# EFR32FG23B010F512IM48 register map
Vendor: Silicon Labs; Series: EFR32; File version: C
CPU: CM33 r0p4, little endian, MPU, FPU, DSP, VTOR, 4 interrupt priority bits, 8 SAU regions
Registers are 32-bit, read-write, reset 0x0 unless marked. A register's access mark holds for its fields unless they carry their own. Offsets are from the block's base; [hi:lo] are bit positions.

## MSC_NS — MSC_NS Registers
Base 0x50030000
Same registers: MSC_S 0x40030000
0x00 IPVERSION ro reset 0x2
  [31:0] IPVERSION — IP Version ID
0x04 READCTRL reset 0x200000
  [21:20] MODE — Read Mode
    0=WS0 (Zero wait-states inserted in fetch or read transfers); 1=WS1 (One wait-state inserted for each fetch or read transfer. See Flash Wait-States table for details); 2=WS2 (Two wait-states inserted for eatch fetch or read transfer. See Flash Wait-States table for details); 3=WS3 (Three wait-states inserted for eatch fetch or read transfer. See Flash Wait-States table for details)
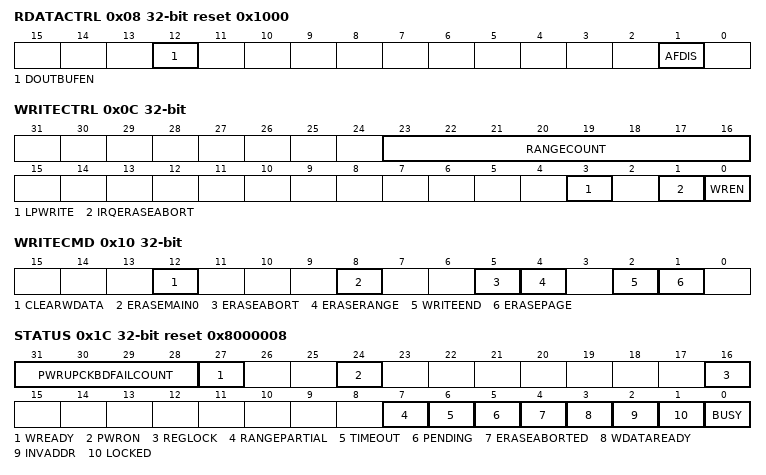
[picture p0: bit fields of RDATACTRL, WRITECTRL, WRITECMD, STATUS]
0x08 RDATACTRL reset 0x1000
  [12] DOUTBUFEN — Flash dout pipeline buffer enable
  [1] AFDIS — Automatic Invalidate Disable
0x0C WRITECTRL
  [23:16] RANGECOUNT — EraseRange Count
  [3] LPWRITE — Low-Power Write
  [1] IRQERASEABORT — Abort Page Erase on Interrupt
  [0] WREN — Enable Write/Erase Controller
0x10 WRITECMD wo
  [12] CLEARWDATA — Clear WDATA state
  [8] ERASEMAIN0 — Mass erase region 0
  [5] ERASEABORT — Abort erase sequence
  [4] ERASERANGE — Erase range of pages
  [2] WRITEEND — End Write Mode
  [1] ERASEPAGE
0x14 ADDRB
  [31:0] ADDRB — Page Erase or Write Address Buffer
0x18 WDATA
  [31:0] DATAW — Write Data
0x1C STATUS ro reset 0x8000008
  [31:28] PWRUPCKBDFAILCOUNT — Flash power up checkerboard pattern chec
  [27] WREADY — Flash Write Ready
  [24] PWRON — Flash power on status
  [16] REGLOCK — Register Lock Status
    0=UNLOCKED; 1=LOCKED
  [7] RANGEPARTIAL — EraseRange with skipped locked pages
  [6] TIMEOUT — Write Command Timeout
  [5] PENDING — Write Command In Queue
  [4] ERASEABORTED — Erase Operation Aborted
  [3] WDATAREADY — WDATA Write Ready
  [2] INVADDR — Invalid Write Address or Erase Page
  [1] LOCKED — Access Locked
  [0] BUSY — Erase/Write Busy
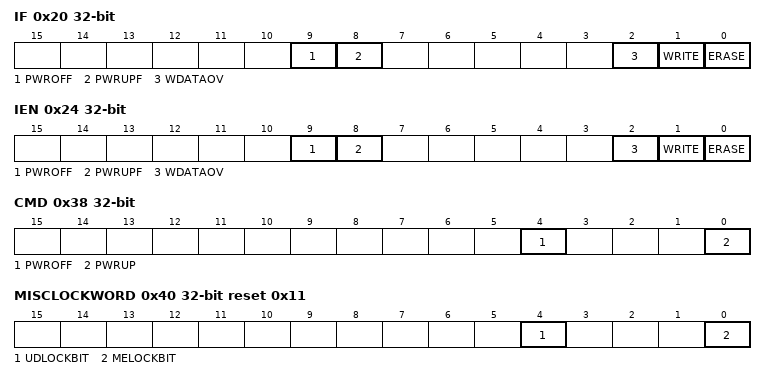
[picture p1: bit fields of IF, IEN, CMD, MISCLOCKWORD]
0x20 IF
  [9] PWROFF — Flash Power Off Sequence Complete Flag
  [8] PWRUPF — Flash Power Up Sequence Complete Flag
  [2] WDATAOV — Host write buffer overflow
  [1] WRITE — Host Write Done Interrupt Read Flag
  [0] ERASE — Host Erase Done Interrupt Read Flag
0x24 IEN
  [9] PWROFF — Flash Power Off Seq done irq enable
  [8] PWRUPF — Flash Power Up Seq done irq enable
  [2] WDATAOV — write data buffer overflow irq enable
  [1] WRITE — Write Done Interrupt enable
  [0] ERASE — Erase Done Interrupt enable
0x34 USERDATASIZE ro reset 0x4
  [5:0] USERDATASIZE
0x38 CMD wo
  [4] PWROFF — Flash power off/sleep command
  [0] PWRUP — Flash Power Up Command
0x3C LOCK wo
  [15:0] LOCKKEY — Configuration Lock
    0=LOCK; 0x1B71=UNLOCK
0x40 MISCLOCKWORD reset 0x11
  [4] UDLOCKBIT — User Data Lock
  [0] MELOCKBIT — Mass Erase Lock
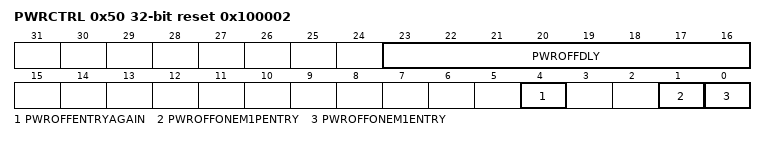
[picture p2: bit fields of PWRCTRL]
0x50 PWRCTRL reset 0x100002
  [23:16] PWROFFDLY — Power down delay
  [4] PWROFFENTRYAGAIN — POWER down flash again in EM1/EM1p
  [1] PWROFFONEM1PENTRY — Power down Flash macro when enter EM1P
  [0] PWROFFONEM1ENTRY — Power down Flash macro when enter EM1
0x120 PAGELOCK0
  [31:0] LOCKBIT — page lock bit
0x124 PAGELOCK1
  [31:0] LOCKBIT — page lock bit

## PFMXPPRF_NS — PFMXPPRF_NS Registers
Base 0x500C4000
Same registers: PFMXPPRF_S 0x400C4000
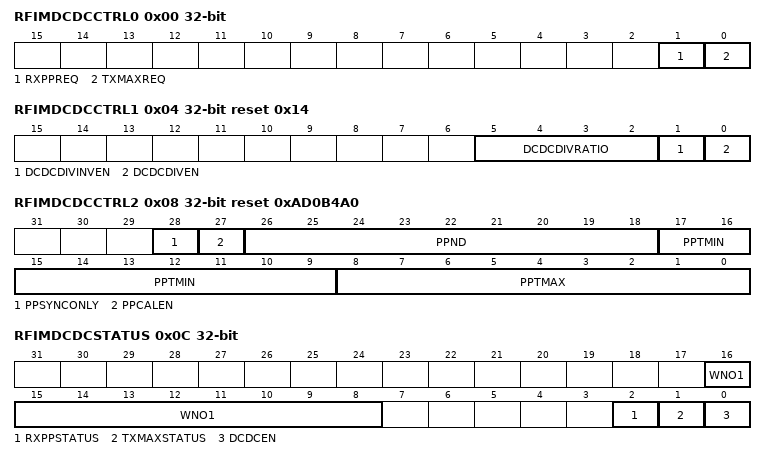
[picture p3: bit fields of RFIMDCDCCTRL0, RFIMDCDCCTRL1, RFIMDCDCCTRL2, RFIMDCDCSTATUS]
0x00 RFIMDCDCCTRL0
  [1] RXPPREQ, [0] TXMAXREQ
0x04 RFIMDCDCCTRL1 reset 0x14
  [5:2] DCDCDIVRATIO
    0=DIVRATIO8 (Dividing master_rf clk by 8, D=50%); 1=DIVRATIO9 (Dividing master_rf clk by 9, D=44.4%); 2=DIVRATIO10 (Dividing master_rf clk by 10, D=40%); 3=DIVRATIO11 (Dividing master_rf clk by 11, D=36.4%); 4=DIVRATIO12 (Dividing master_rf clk by 12, D=50%); 5=DIVRATIO13 (Dividing master_rf clk by 13, D=46.2%); 6=DIVRATIO14 (Dividing master_rf clk by 14, D=42.9%); 7=DIVRATIO15 (Dividing master_rf clk by 15, D=40%); 8=DIVRATIO16 (Dividing master_rf clk by 16, D=50%); 9=DIVRATIO17 (Dividing master_rf clk by 17, D=47.1%); 10=DIVRATIO18 (Dividing master_rf clk by 18, D=44.4%); 11=DIVRATIO19 (Dividing master_rf clk by 19, D=42.1%); 12=DIVRATIO20 (Dividing master_rf clk by 20, D=60%); 13=DIVRATIO21 (Dividing master_rf clk by 21, D=57.1%); 14=DIVRATIO22 (Dividing master_rf clk by 22, D=54.5%); 15=DIVRATIO23 (Dividing master_rf clk by 23, D=52.2%)
  [1] DCDCDIVINVEN — DCDC DIV Inverter Enable
  [0] DCDCDIVEN — DCDC DIV Enable
0x08 RFIMDCDCCTRL2 reset 0xAD0B4A0
  [28] PPSYNCONLY — Pulse Pairing Sync Only
  [27] PPCALEN — Pulse Pairing Calibration Loop Enable
  [26:18] PPND — Pulse Pairing Period
  [17:9] PPTMIN — Pulse Pairing Time Min
  [8:0] PPTMAX — Pulse Pairing Time Max
0x0C RFIMDCDCSTATUS ro
  [16:8] WNO1 — Cal Loop WNO1 value
  [2] RXPPSTATUS
  [1] TXMAXSTATUS
  [0] DCDCEN — DCDC Enable Status
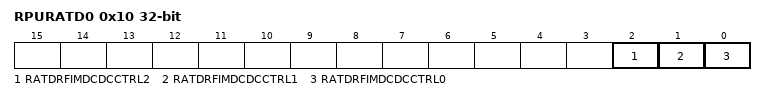
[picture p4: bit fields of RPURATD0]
0x10 RPURATD0 — Protected register address = (RPURATD register index X 32 + RPURATD bit index) X 4.
  [2] RATDRFIMDCDCCTRL2 — RFIMDCDCCTRL2 Protection Bit
  [1] RATDRFIMDCDCCTRL1 — RFIMDCDCCTRL1 Protection Bit
  [0] RATDRFIMDCDCCTRL0 — RFIMDCDCCTRL0 Protection Bit
